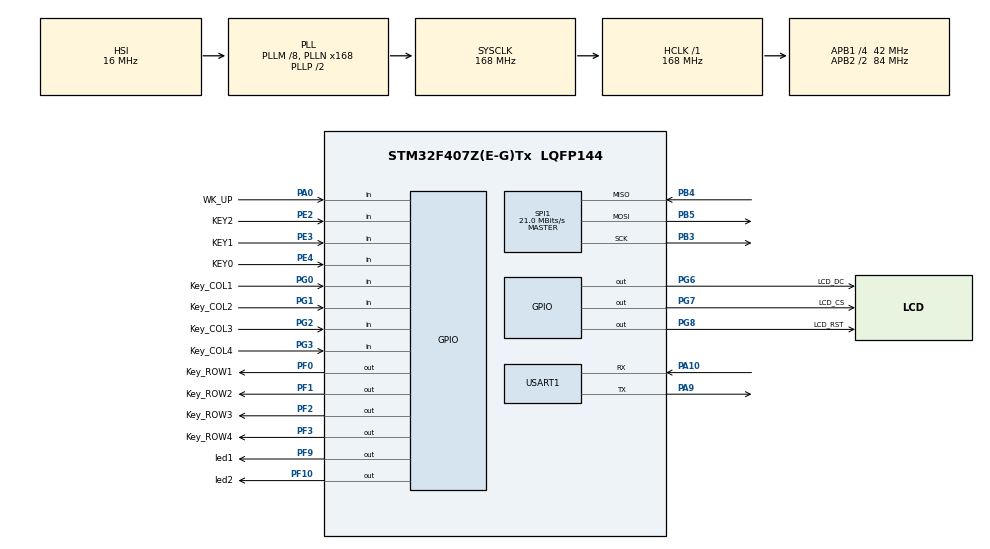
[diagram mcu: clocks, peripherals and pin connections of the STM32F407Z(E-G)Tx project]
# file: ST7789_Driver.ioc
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Dma.Request0=SPI1_TX
Dma.Request1=SPI1_RX
Dma.SPI1_RX.1.Direction=DMA_PERIPH_TO_MEMORY
Dma.SPI1_RX.1.FIFOMode=DMA_FIFOMODE_DISABLE
Dma.SPI1_RX.1.Instance=DMA2_Stream0
Dma.SPI1_RX.1.MemDataAlignment=DMA_MDATAALIGN_HALFWORD
Dma.SPI1_RX.1.MemInc=DMA_MINC_ENABLE
Dma.SPI1_RX.1.Mode=DMA_NORMAL
Dma.SPI1_RX.1.PeriphDataAlignment=DMA_PDATAALIGN_HALFWORD
Dma.SPI1_RX.1.PeriphInc=DMA_PINC_DISABLE
Dma.SPI1_RX.1.Priority=DMA_PRIORITY_LOW
Dma.SPI1_TX.0.Direction=DMA_MEMORY_TO_PERIPH
Dma.SPI1_TX.0.FIFOMode=DMA_FIFOMODE_DISABLE
Dma.SPI1_TX.0.Instance=DMA2_Stream3
Dma.SPI1_TX.0.MemDataAlignment=DMA_MDATAALIGN_HALFWORD
Dma.SPI1_TX.0.MemInc=DMA_MINC_ENABLE
Dma.SPI1_TX.0.Mode=DMA_NORMAL
Dma.SPI1_TX.0.PeriphDataAlignment=DMA_PDATAALIGN_HALFWORD
Dma.SPI1_TX.0.PeriphInc=DMA_PINC_DISABLE
Dma.SPI1_TX.0.Priority=DMA_PRIORITY_LOW
Mcu.Family=STM32F4
Mcu.Name=STM32F407Z(E-G)Tx
Mcu.Package=LQFP144
NVIC.DMA2_Stream0_IRQn=true\:0\:0\:false\:false\:true\:false\:true
NVIC.DMA2_Stream3_IRQn=true\:0\:0\:false\:false\:true\:false\:true
NVIC.PriorityGroup=NVIC_PRIORITYGROUP_4
NVIC.TIM3_IRQn=true\:0\:0\:false\:false\:true\:true\:true
NVIC.USART1_IRQn=true\:0\:0\:false\:false\:true\:true\:true
PA0-WKUP.GPIO_Label=WK_UP
PA0-WKUP.GPIO_PuPd=GPIO_PULLDOWN
PA0-WKUP.Signal=GPIO_Input
PA10.Mode=Asynchronous
PA10.Signal=USART1_RX
PA13.Mode=Serial_Wire
PA13.Signal=SYS_JTMS-SWDIO
PA14.Mode=Serial_Wire
PA14.Signal=SYS_JTCK-SWCLK
PA9.Mode=Asynchronous
PA9.Signal=USART1_TX
PB3.Mode=Full_Duplex_Master
PB3.Signal=SPI1_SCK
PB4.Mode=Full_Duplex_Master
PB4.Signal=SPI1_MISO
PB5.Mode=Full_Duplex_Master
PB5.Signal=SPI1_MOSI
PC14-OSC32_IN.Mode=LSE-External-Oscillator
PC14-OSC32_IN.Signal=RCC_OSC32_IN
PC15-OSC32_OUT.Mode=LSE-External-Oscillator
PC15-OSC32_OUT.Signal=RCC_OSC32_OUT
PE2.GPIO_Label=KEY2
PE2.GPIO_PuPd=GPIO_PULLUP
PE2.Signal=GPIO_Input
PE3.GPIO_Label=KEY1
PE3.GPIO_PuPd=GPIO_PULLUP
PE3.Signal=GPIO_Input
PE4.GPIO_Label=KEY0
PE4.GPIO_PuPd=GPIO_PULLUP
PE4.Signal=GPIO_Input
PF0.GPIO_Label=Key_ROW1
PF0.GPIO_Speed=GPIO_SPEED_FREQ_HIGH
PF0.Signal=GPIO_Output
PF1.GPIO_Label=Key_ROW2
PF1.GPIO_Speed=GPIO_SPEED_FREQ_HIGH
PF1.Signal=GPIO_Output
PF10.GPIO_Label=led2
PF10.Signal=GPIO_Output
PF2.GPIO_Label=Key_ROW3
PF2.GPIO_Speed=GPIO_SPEED_FREQ_HIGH
PF2.Signal=GPIO_Output
PF3.GPIO_Label=Key_ROW4
PF3.GPIO_Speed=GPIO_SPEED_FREQ_HIGH
PF3.Signal=GPIO_Output
PF9.GPIO_Label=led1
PF9.Signal=GPIO_Output
PG0.GPIO_Label=Key_COL1
PG0.GPIO_PuPd=GPIO_PULLUP
PG0.Signal=GPIO_Input
PG1.GPIO_Label=Key_COL2
PG1.GPIO_PuPd=GPIO_PULLUP
PG1.Signal=GPIO_Input
PG2.GPIO_Label=Key_COL3
PG2.GPIO_PuPd=GPIO_PULLUP
PG2.Signal=GPIO_Input
PG3.GPIO_Label=Key_COL4
PG3.GPIO_PuPd=GPIO_PULLUP
PG3.Signal=GPIO_Input
PG6.GPIO_Label=LCD_DC
PG6.GPIO_PuPd=GPIO_PULLDOWN
PG6.GPIO_Speed=GPIO_SPEED_FREQ_VERY_HIGH
PG6.PinState=GPIO_PIN_SET
PG6.Signal=GPIO_Output
PG7.GPIO_Label=LCD_CS
PG7.GPIO_PuPd=GPIO_PULLUP
PG7.GPIO_Speed=GPIO_SPEED_FREQ_VERY_HIGH
PG7.PinState=GPIO_PIN_SET
PG7.Signal=GPIO_Output
PG8.GPIO_Label=LCD_RST
PG8.GPIO_PuPd=GPIO_PULLUP
PG8.GPIO_Speed=GPIO_SPEED_FREQ_VERY_HIGH
PG8.PinState=GPIO_PIN_SET
PG8.Signal=GPIO_Output
PH0-OSC_IN.Mode=HSE-External-Oscillator
PH0-OSC_IN.Signal=RCC_OSC_IN
PH1-OSC_OUT.Mode=HSE-External-Oscillator
PH1-OSC_OUT.Signal=RCC_OSC_OUT
ProjectManager.HeapSize=0x200
ProjectManager.StackSize=0x400
ProjectManager.TargetToolchain=MDK-ARM V5.27
RCC.48MHZClocksFreq_Value=84000000
RCC.AHBFreq_Value=168000000
RCC.APB1CLKDivider=RCC_HCLK_DIV4
RCC.APB1Freq_Value=42000000
RCC.APB1TimFreq_Value=84000000
RCC.APB2CLKDivider=RCC_HCLK_DIV2
RCC.APB2Freq_Value=84000000
RCC.APB2TimFreq_Value=168000000
RCC.CortexFreq_Value=168000000
RCC.HCLKFreq_Value=168000000
RCC.HSE_VALUE=25000000
RCC.HSI_VALUE=16000000
RCC.PLLM=8
RCC.PLLN=168
RCC.SYSCLKFreq_VALUE=168000000
RCC.SYSCLKSource=RCC_SYSCLKSOURCE_PLLCLK
RCC.VCOOutputFreq_Value=336000000
SPI1.BaudRatePrescaler=SPI_BAUDRATEPRESCALER_4
SPI1.CalculateBaudRate=21.0 MBits/s
SPI1.Direction=SPI_DIRECTION_2LINES
SPI1.Mode=SPI_MODE_MASTER
SPI1.VirtualType=VM_MASTER
TIM3.Period=99
TIM3.Prescaler=8399
USART1.VirtualMode=VM_ASYNC
VP_TIM3_VS_ClockSourceINT.Mode=Internal
board=custom

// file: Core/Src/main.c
/* USER CODE BEGIN Header */
/**
  ******************************************************************************
  * @file           : main.c
  * @brief          : Main program body
  ******************************************************************************
  * @attention
  *
  * <h2><center>&copy; Copyright (c) 2021 STMicroelectronics.
  * All rights reserved.</center></h2>
  *
  * This software component is licensed by ST under BSD 3-Clause license,
  * the "License"; You may not use this file except in compliance with the
  * License. You may obtain a copy of the License at:
  *                        opensource.org/licenses/BSD-3-Clause
  *
  ******************************************************************************
  */
/* USER CODE END Header */
#include "main.h"
#include "dma.h"
#include "spi.h"
#include "tim.h"
#include "usart.h"
#include "gpio.h"

/* USER CODE BEGIN Includes */
#include "lcd.h"
#include "string.h"
#include "lv_port_disp.h"
#include "lv_demo_widgets.h"
#include "../../lv_examples.h"
#include  "keypad.h"

/* USER CODE END Includes */

void SystemClock_Config(void);

/* USER CODE BEGIN 0 */
extern uint8_t key_value;
/* USER CODE END 0 */

int main(void)
{
  /* USER CODE BEGIN 1 */
  char temp_buffer[50] = {0};
  /* USER CODE END 1 */

  /* MCU Configuration--------------------------------------------------------*/

  /* Reset of all peripherals, Initializes the Flash interface and the Systick. */
  HAL_Init();

  /* Configure the system clock */
  SystemClock_Config();

  /* Initialize all configured peripherals */
  MX_GPIO_Init();
  MX_DMA_Init();
  MX_SPI1_Init();
  MX_USART1_UART_Init();
  MX_TIM3_Init();
  /* USER CODE BEGIN 2 */
  lcd_init();
  TIM3_Init();
  LCD_ShowChar_Str(20, 80, 20, "key_test", 0xffff, 0, 32);

//  lv_init();           //
//  lv_port_disp_init(); //
  //lv_demo_widgets();      //
  //lv_ex_get_started_1();
  //lv_demo_keypad_encoder();
	//lv_ex_slider_2();
//  lv_ex_calendar_1();
  /* USER CODE END 2 */

  /* Infinite loop */
  while (1)
  {

    /* USER CODE BEGIN 3 */
//    if (key_value!=0xff)
//    {
//      sprintf(temp_buffer, "%s%d", "key_value is:  ", key_value);
//      LCD_ShowChar_Str(20, 120, 20, temp_buffer, 0xffff, 0, 24);
//    }
    key_value=KeyPad_GetKeyValue();

    //printf("\r\nkeycode is:%0x\r\n", KeyPad_GetKeyValue());
//    lv_task_handler(); //  tasks
  }
  /* USER CODE END 3 */
}

void SystemClock_Config(void)
{
  RCC_OscInitTypeDef RCC_OscInitStruct = {0};
  RCC_ClkInitTypeDef RCC_ClkInitStruct = {0};

  /** Configure the main internal regulator output voltage
  */
  __HAL_RCC_PWR_CLK_ENABLE();
  __HAL_PWR_VOLTAGESCALING_CONFIG(PWR_REGULATOR_VOLTAGE_SCALE1);
  /** Initializes the RCC Oscillators according to the specified parameters
  * in the RCC_OscInitTypeDef structure.
  */
  RCC_OscInitStruct.OscillatorType = RCC_OSCILLATORTYPE_HSI;
  RCC_OscInitStruct.HSIState = RCC_HSI_ON;
  RCC_OscInitStruct.HSICalibrationValue = RCC_HSICALIBRATION_DEFAULT;
  RCC_OscInitStruct.PLL.PLLState = RCC_PLL_ON;
  RCC_OscInitStruct.PLL.PLLSource = RCC_PLLSOURCE_HSI;
  RCC_OscInitStruct.PLL.PLLM = 8;
  RCC_OscInitStruct.PLL.PLLN = 168;
  RCC_OscInitStruct.PLL.PLLP = RCC_PLLP_DIV2;
  RCC_OscInitStruct.PLL.PLLQ = 4;
  if (HAL_RCC_OscConfig(&RCC_OscInitStruct) != HAL_OK)
  {
    Error_Handler();
  }
  /** Initializes the CPU, AHB and APB buses clocks
  */
  RCC_ClkInitStruct.ClockType = RCC_CLOCKTYPE_HCLK|RCC_CLOCKTYPE_SYSCLK
                              |RCC_CLOCKTYPE_PCLK1|RCC_CLOCKTYPE_PCLK2;
  RCC_ClkInitStruct.SYSCLKSource = RCC_SYSCLKSOURCE_PLLCLK;
  RCC_ClkInitStruct.AHBCLKDivider = RCC_SYSCLK_DIV1;
  RCC_ClkInitStruct.APB1CLKDivider = RCC_HCLK_DIV4;
  RCC_ClkInitStruct.APB2CLKDivider = RCC_HCLK_DIV2;

  if (HAL_RCC_ClockConfig(&RCC_ClkInitStruct, FLASH_LATENCY_5) != HAL_OK)
  {
    Error_Handler();
  }
}

void Error_Handler(void)
{
  __disable_irq();
  while (1)
  {
  }
}

/************************ (C) COPYRIGHT STMicroelectronics *****END OF FILE****/
